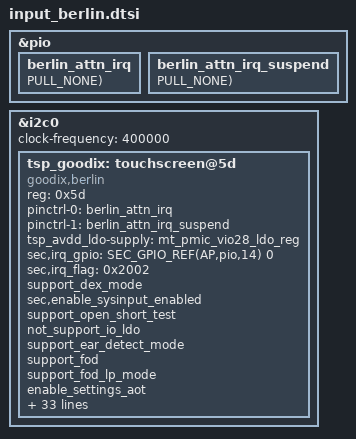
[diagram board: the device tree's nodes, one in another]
&pio {
	berlin_attn_irq: berlin_attn_irq {
		GPIO_CONFIG_PUD(AP,pio,14, FUNC_INPUT_WAKEUP, PULL_NONE);
	};

	berlin_attn_irq_suspend: berlin_attn_irq_suspend {
		GPIO_CONFIG_PUD(AP,pio,14, FUNC_INPUT, PULL_NONE);
	};
};

&i2c0 {
	#address-cells = <1>;
	#size-cells = <0>;
	status = "okay";
	clock-frequency = <400000>;

	tsp_goodix: touchscreen@5d {
		status = "okay";
		compatible = "goodix,berlin";
		reg = <0x5d>;
		pinctrl-names = "on_state", "off_state";
		pinctrl-0 = <&berlin_attn_irq>;
		pinctrl-1 = <&berlin_attn_irq_suspend>;
		tsp_io_ldo-supply = <&NC>;
		tsp_avdd_ldo-supply = <&mt_pmic_vio28_ldo_reg>;
		sec,irq_gpio = <SEC_GPIO_REF(AP,pio,14) 0>;
		sec,irq_flag = <0x2002>; /* IRQF_TRIGGER_FALLING | IRQF_ONESHOT */
		support_dex_mode;
		sec,enable_sysinput_enabled;
		support_open_short_test;
	};
};

/* /home/dpi/qb5_8814/workspace/P4_1716/android/kernel/kmodule/input/touchscreen/goodix/berlin/dts/input-mtk-tsp-berlin.a34x.dtsi */
&tsp_goodix {
	status = "okay";
	/delete-property/ tsp_io_ldo-supply;
	not_support_io_ldo;
	support_ear_detect_mode;
	support_fod;
	support_fod_lp_mode;
	enable_settings_aot;
	sec,bitmask_unload = <12 0x804>; /* bitshift bitmask. this is for focaltech panel */
	sec,refresh_rate_enable;
	sec,enable_esd_check;

	sec,max_coords = <1080 2400>;
	//sec,firmware_name = "gt9895_a33x.bin";
	sec,bringup = <1>;

	sec,ic_type = <2>; //GT9895
	sec,max_drv_num = <17>;
	sec,max_sen_num = <35>;
	sec,drv_map = <35 36 37 38 39 40 41 42 43 44
			45 46 47 48 49 50 51>;
	sec,sen_map = <0 1 2 3 4 5 6 7 8 9 10 11 12
			13 14 15 16 17 18 19 20 21
			22 23 24 25 26 27 28 29 30
			31 32 33 34>;
	sec,short_test_time_reg = <0x1479E>;
	sec,short_test_status_reg = <0x13400>;
	sec,short_test_result_reg = <0x13408>;
	sec,drv_drv_reg = <0x13446>;
	sec,sen_sen_reg = <0x136EE>;
	sec,drv_sen_reg = <0x14152>;
	sec,diff_code_reg = <0x14734>;
	sec,production_test_addr = <0x15D4C>;
	sec,switch_freq_cmd = <0xB1>;
	sec,switch_cfg_cmd = <0x64>;
	sec,snr_cmd = <0x65>;
	sec,sensitive_cmd = <0x66>;

	sec,isp_ram_reg = <0x23800>;
	sec,flash_cmd_reg = <0x12400>;
	sec,isp_buffer_reg = <0x12410>;
	sec,config_data_reg = <0x3E000>;
	sec,misctl_reg = <0xD804>;
	sec,watch_dog_reg = <0xD040>;
	sec,config_id_reg = <0x10076>;
	sec,enable_misctl_val = <0x20700000>;
};

/* /home/dpi/qb5_8814/workspace/P4_1716/android/kernel/kmodule/input/touchscreen/goodix/berlin/dts/input-mtk-tsp-berlin.a34x.01.dtsi */
&tsp_goodix {
	sec,max_coords = <1080 2340>;
	sec,firmware_name = "tsp_goodix/gt9895_a34x.bin";
	sec,bringup = <0>;
};
